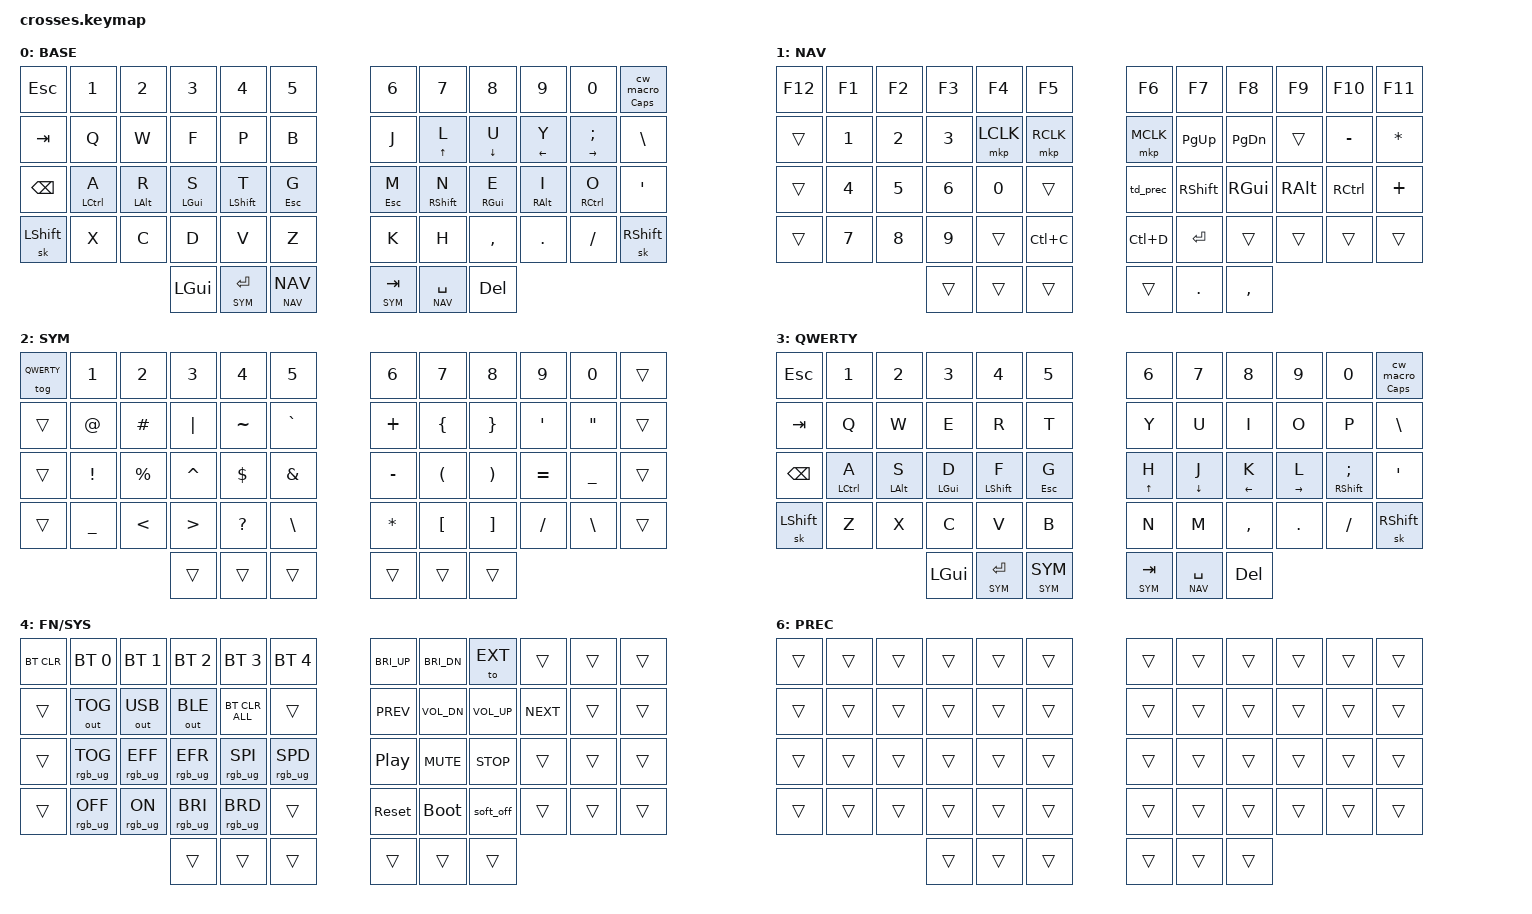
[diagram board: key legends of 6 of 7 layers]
/*
 * Crosses 54 — ZMK keymap (synchronized with eyelash_sofle / kanata.kbd)
 *
 * Layers:
 *   0 = BASE    Colemak-DH + HRMs + top-row hold-arrows
 *   1 = NAV     Navigation / numpad / clipboard shortcuts
 *   2 = SYM     Symbols (+ pos 0 toggles QWERTY)
 *   3 = QWERTY  QWERTY alpha layer (toggle via SYM, pos 0)
 *   4 = FN      Function / media / BT / RGB / system (tri-layer NAV+SYM)
 *   5 = EXT     Extended / special keys (toggle via FN, &to EXT)
 *   6 = PREC    Trackball precision (all &trans; NAV pos 30: hold = on while held,
 *               double-tap = toggle)
 *
 * Home-row & top-row holds (BASE Colemak-DH):
 *   L (mods):   A=Ctrl  R=Alt  S=GUI  T=Shift (hsl)   G=ESC (hla)
 *   R (arrows): L=UP    U=DOWN  Y=LEFT  ;=RIGHT (top row)
 *   R (mods):   M=ESC   N=Shift (hsr)  E=GUI (hmr)  I=Alt (hmr)  O=Ctrl (hmr) (home row)
 *
 * Home-row holds (QWERTY):
 *   L (mods):   A=Ctrl  S=Alt  D=GUI  F=Shift (hsl)   G=ESC (hla)
 *   R (arrows): H=UP    J=DOWN  K=LEFT  L=RIGHT  ;=Shift (hsr)
 */

#include <behaviors.dtsi>
#include <dt-bindings/zmk/bt.h>
#include <dt-bindings/zmk/keys.h>
#include <dt-bindings/zmk/outputs.h>
#include <dt-bindings/zmk/pointing.h>
#include <dt-bindings/zmk/rgb.h>
#include <input/processors.dtsi>

#define BASE   0
#define NAV    1
#define SYM    2
#define QWERTY 3
#define FN     4
#define EXT    5
#define PREC   6

#define LMODS  &kp LCTRL &kp LALT &kp LGUI &kp LSHFT
#define EDIT   &kp K_UNDO &kp K_CUT &kp K_COPY &kp K_PASTE &kp K_REDO

&soft_off { hold-time-ms = <2000>; };

&caps_word { continue-list = <UNDERSCORE MINUS BACKSPACE DELETE>; };

&sk { ignore-modifiers; };

/ {
    chosen { zmk,physical-layout = &gggw_crosses_54_layout; };

    conditional_layers {
        compatible = "zmk,conditional-layers";
        tri_layer {
            if-layers = <NAV SYM>;
            then-layer = <FN>;
        };
    };

    macros {
        cw_macro: cw_macro {
            compatible = "zmk,behavior-macro-one-param";
            #binding-cells = <1>;
            bindings = <&caps_word>;
        };
    };

    behaviors {
        /* Home-row mods (left hand) — Ctrl / Alt / GUI only (A / R / S). */
        hml: home_row_mod_left {
            compatible = "zmk,behavior-hold-tap";
            #binding-cells = <2>;
            flavor = "balanced";
            tapping-term-ms = <280>;
            quick-tap-ms = <175>;
            require-prior-idle-ms = <150>;
            bindings = <&sk>, <&kp>;
            hold-trigger-key-positions = <
                /* Full right hand */
                6  7  8  9  10 11
                18 19 20 21 22 23
                30 31 32 33 34 35
                42 43 44 45 46 47
                51 52 53
            >;
            hold-trigger-on-release;
        };

        /* Left-hand SHIFT (T on Colemak, F on QWERTY) */
        hsl: home_shift_left {
            compatible = "zmk,behavior-hold-tap";
            #binding-cells = <2>;
            flavor = "balanced";
            tapping-term-ms = <280>;
            quick-tap-ms = <175>;
            require-prior-idle-ms = <150>;
            bindings = <&sk>, <&kp>;
            hold-trigger-key-positions = <
                /* Full right hand */
                6  7  8  9  10 11
                18 19 20 21 22 23
                30 31 32 33 34 35
                42 43 44 45 46 47
                51 52 53
            >;
            hold-trigger-on-release;
        };

        /* Right-hand mods (E=GUI, I=Alt, O=Ctrl on Colemak). */
        hmr: home_row_mod_right {
            compatible = "zmk,behavior-hold-tap";
            #binding-cells = <2>;
            flavor = "balanced";
            tapping-term-ms = <280>;
            quick-tap-ms = <175>;
            require-prior-idle-ms = <150>;
            bindings = <&sk>, <&kp>;
            hold-trigger-key-positions = <
                /* Full left hand */
                0  1  2  3  4  5
                12 13 14 15 16 17
                24 25 26 27 28 29
                36 37 38 39 40 41
                48 49 50
            >;
            hold-trigger-on-release;
        };

        /* Right-hand SHIFT (N on Colemak, ; on QWERTY). */
        hsr: home_shift_right {
            compatible = "zmk,behavior-hold-tap";
            #binding-cells = <2>;
            flavor = "balanced";
            tapping-term-ms = <280>;
            quick-tap-ms = <175>;
            require-prior-idle-ms = <150>;
            bindings = <&sk>, <&kp>;
            hold-trigger-key-positions = <
                /* Full left hand */
                0  1  2  3  4  5
                12 13 14 15 16 17
                24 25 26 27 28 29
                36 37 38 39 40 41
                48 49 50
            >;
            hold-trigger-on-release;
        };

        /* Right-hand hold-arrows (top row Colemak, home row QWERTY) & hold-ESC (M) */
        hra: home_row_arrow {
            compatible = "zmk,behavior-hold-tap";
            #binding-cells = <2>;
            flavor = "tap-preferred";
            tapping-term-ms = <200>;
            quick-tap-ms = <175>;
            require-prior-idle-ms = <150>;
            bindings = <&kp>, <&kp>;
            hold-trigger-key-positions = <
                0  1  2  3  4  5
                12 13 14 15 16 17
                24 25 26 27 28 29
                36 37 38 39 40 41
                48 49 50
            >;
            hold-trigger-on-release;
        };

        /* Left-hand hold-arrow (G=ESC) */
        hla: home_left_arrow {
            compatible = "zmk,behavior-hold-tap";
            #binding-cells = <2>;
            flavor = "tap-preferred";
            tapping-term-ms = <200>;
            quick-tap-ms = <175>;
            require-prior-idle-ms = <150>;
            bindings = <&kp>, <&kp>;
            hold-trigger-key-positions = <
                6  7  8  9  10 11
                18 19 20 21 22 23
                30 31 32 33 34 35
                42 43 44 45 46 47
                51 52 53
            >;
            hold-trigger-on-release;
        };

        lt_thumb: layer_tap_thumb {
            compatible = "zmk,behavior-hold-tap";
            #binding-cells = <2>;
            flavor = "tap-preferred";
            tapping-term-ms = <180>;
            quick-tap-ms = <150>;
            bindings = <&mo>, <&kp>;
        };

        ltq: layer_tap_or_sticky {
            compatible = "zmk,behavior-hold-tap";
            #binding-cells = <2>;
            flavor = "balanced";
            tapping-term-ms = <200>;
            quick-tap-ms = <0>;
            bindings = <&mo>, <&sl>;
        };

        kp_slh: kp_tap_sticky_layer_hold {
            compatible = "zmk,behavior-hold-tap";
            #binding-cells = <2>;
            flavor = "tap-preferred";
            tapping-term-ms = <200>;
            quick-tap-ms = <120>;
            require-prior-idle-ms = <150>;
            bindings = <&sl>, <&kp>;
        };

        /* NAV pos 30 (under middle click): hold = precision while held
         * (starts after 200 ms, or at once when another key is pressed),
         * double-tap = toggle precision on/off. */
        td_prec: tap_dance_precision {
            compatible = "zmk,behavior-tap-dance";
            #binding-cells = <0>;
            tapping-term-ms = <200>;
            bindings = <&mo PREC>, <&tog PREC>;
        };

        cw_caps: caps_word_tap_caps_hold {
            compatible = "zmk,behavior-hold-tap";
            #binding-cells = <2>;
            flavor = "tap-preferred";
            tapping-term-ms = <200>;
            quick-tap-ms = <150>;
            bindings = <&kp>, <&cw_macro>;
        };
    };

    keymap {
        compatible = "zmk,keymap";

        /* ==================================================================
         * LAYER 0 — BASE (Colemak-DH)
         * ================================================================== */
        base_layer {
            display-name = "BASE";
            bindings = <
&kp ESC        &kp N1         &kp N2         &kp N3        &kp N4              &kp N5            &kp N6              &kp N7         &kp N8        &kp N9         &kp N0            &cw_caps CAPS 0
&kp TAB        &kp Q          &kp W          &kp F         &kp P               &kp B             &kp J               &hra UP L      &hra DOWN U   &hra LEFT Y    &hra RIGHT SEMI   &kp BSLH
&kp BACKSPACE  &hml LCTRL A   &hml LALT R    &hml LGUI S   &hsl LSHFT T        &hla ESC G        &hra ESC M          &hsr RSHFT N   &hmr RGUI E   &hmr RALT I    &hmr RCTRL O      &kp APOS
&sk LSHFT      &kp X          &kp C          &kp D         &kp V               &kp Z             &kp K               &kp H          &kp COMMA     &kp DOT        &kp FSLH          &sk RSHFT
                                             &kp LGUI      &kp_slh SYM ENTER   &ltq NAV NAV      &lt_thumb SYM TAB   &kp_slh NAV SPACE &kp DEL
            >;
        };

        /* ==================================================================
         * LAYER 1 — NAV
         *   - Left hand: Numpad (1-9), mouse clicks (L/M/R), Cut/Copy
         *   - Right hand: PgUp/PgDn, mods (Shift/GUI/Alt/Ctrl), Return, +, *
         * ================================================================== */
        nav_layer {
            display-name = "NAV";
            bindings = <
&kp F12     &kp F1      &kp F2      &kp F3      &kp F4      &kp F5      &kp F6      &kp F7      &kp F8      &kp F9      &kp F10     &kp F11
&trans      &kp N1      &kp N2      &kp N3      &mkp LCLK   &mkp RCLK   &mkp MCLK   &kp PG_UP   &kp PG_DN   &trans      &kp MINUS   &kp ASTRK
&trans      &kp N4      &kp N5      &kp N6      &kp N0      &trans      &td_prec    &kp RSHFT   &kp RGUI    &kp RALT    &kp RCTRL   &kp PLUS
&trans      &kp N7      &kp N8      &kp N9      &trans      &kp LC(C)   &kp LC(D)   &kp ENTER   &trans      &trans      &trans      &trans
                                    &trans   &trans      &trans      &trans      &kp DOT     &kp COMMA
            >;
        };

        /* ==================================================================
         * LAYER 2 — SYM
         *   Top-left (pos 0) toggles QWERTY (mirrors kanata @tog_qw).
         *   Symbol layout mirrors kanata.kbd / sofle.
         * ================================================================== */
        sym_layer {
            display-name = "SYM";
            bindings = <
&tog QWERTY &kp N1      &kp N2      &kp N3      &kp N4      &kp N5      &kp N6       &kp N7       &kp N8       &kp N9       &kp N0       &trans
&trans      &kp AT      &kp HASH    &kp PIPE    &kp TILDE   &kp GRAVE   &kp PLUS     &kp LBRC     &kp RBRC     &kp APOS     &kp DQT      &trans
&trans      &kp EXCL    &kp PRCNT   &kp CARET   &kp DLLR    &kp AMPS    &kp MINUS    &kp LPAR     &kp RPAR     &kp EQUAL    &kp UNDER    &trans
&trans      &kp UNDER   &kp LT      &kp GT      &kp QMARK   &kp BSLH    &kp ASTRK    &kp LBKT     &kp RBKT     &kp FSLH     &kp BSLH     &trans
                                    &trans      &trans      &trans      &trans       &trans       &trans
            >;
        };

        /* ==================================================================
         * LAYER 3 — QWERTY (toggle via SYM pos 0)
         * ================================================================== */
        qwerty_layer {
            display-name = "QWERTY";
            bindings = <
&kp ESC        &kp N1         &kp N2        &kp N3         &kp N4              &kp N5            &kp N6              &kp N7         &kp N8        &kp N9         &kp N0            &cw_caps CAPS 0
&kp TAB        &kp Q          &kp W         &kp E          &kp R               &kp T             &kp Y               &kp U          &kp I         &kp O          &kp P             &kp BSLH
&kp BACKSPACE  &hml LCTRL A   &hml LALT S   &hml LGUI D    &hsl LSHFT F        &hla ESC G        &hra UP H           &hra DOWN J    &hra LEFT K   &hra RIGHT L   &hsr RSHFT SEMI   &kp APOS
&sk LSHFT      &kp Z          &kp X         &kp C          &kp V               &kp B             &kp N               &kp M          &kp COMMA     &kp DOT        &kp FSLH          &sk RSHFT
                                             &kp LGUI          &kp_slh SYM ENTER &ltq SYM SYM      &lt_thumb SYM TAB   &kp_slh NAV SPACE &kp DEL
            >;
        };

        /* ==================================================================
         * LAYER 4 — FN / Media / System / BT (tri-layer NAV+SYM)
         * ================================================================== */
        fn_layer {
            display-name = "FN/SYS";
            bindings = <
&bt BT_CLR &bt BT_SEL 0     &bt BT_SEL 1      &bt BT_SEL 2     &bt BT_SEL 3     &bt BT_SEL 4      &kp C_BRI_UP  &kp C_BRI_DN  &to EXT      &trans  &trans  &trans
&trans     &out OUT_TOG     &out OUT_USB      &out OUT_BLE     &bt BT_CLR_ALL   &trans            &kp C_PREV    &kp C_VOL_DN  &kp C_VOL_UP &kp C_NEXT &trans &trans
&trans     &rgb_ug RGB_TOG  &rgb_ug RGB_EFF   &rgb_ug RGB_EFR  &rgb_ug RGB_SPI  &rgb_ug RGB_SPD   &kp C_PP      &kp C_MUTE    &kp C_STOP   &trans  &trans  &trans
&trans     &rgb_ug RGB_OFF  &rgb_ug RGB_ON    &rgb_ug RGB_BRI  &rgb_ug RGB_BRD  &trans            &sys_reset    &bootloader   &soft_off    &trans  &trans  &trans
                                              &trans           &trans           &trans            &trans        &trans        &trans
            >;
        };

        /* ==================================================================
         * LAYER 5 — EXT / Special keys (toggle in FN via &to EXT)
         * ================================================================== */
        ext_layer {
            display-name = "EXT";
            bindings = <
&to BASE   &kp PSCRN     &kp SLCK      &kp PAUSE_BREAK  &kp KP_NUM    &trans          &kp INS       &kp HOME      &kp PG_UP     &trans        &trans        &trans
&trans     &kp F11       &kp F12       &kp K_APP        &kp CAPS      &trans          &kp DEL       &kp END       &kp PG_DN     &trans        &trans        &trans
&trans     LMODS                                                      &trans          &kp LEFT      &kp DOWN      &kp UP        &kp RIGHT     &trans        &trans
&trans     EDIT                                                                       &kp K_FIND    &kp C_AL_LOCK &trans        &trans        &trans        &to BASE
                                       &to BASE         &trans        &trans          &to BASE      &trans        &trans
            >;
        };

        /* ==================================================================
         * LAYER 6 — PREC (trackball precision)
         *   All &trans, so keys behave as the layer below. The trackball
         *   listeners in crosses_right.overlay slow the balls on this layer.
         * ================================================================== */
        prec_layer {
            display-name = "PREC";
            bindings = <
&trans &trans &trans &trans &trans &trans  &trans &trans &trans &trans &trans &trans
&trans &trans &trans &trans &trans &trans  &trans &trans &trans &trans &trans &trans
&trans &trans &trans &trans &trans &trans  &trans &trans &trans &trans &trans &trans
&trans &trans &trans &trans &trans &trans  &trans &trans &trans &trans &trans &trans
                     &trans &trans &trans  &trans &trans &trans
            >;
        };
    };
};

/* Right half only. CROSSES_RIGHT_HALF is defined in config/crosses_right.overlay,
 * which only the right half loads. The shield sets the sensor CPI and the
 * listener's base processors after that overlay, so they are overridden here:
 * the keymap loads after the shield. */
#ifdef CROSSES_RIGHT_HALF
&trackball_central {
    /* The PMW3610 only takes 200-CPI steps (850 would round down to 800),
     * so 850 is made from 1000 CPI x 17/20 below. */
    cpi = <1000>;
};

&trackball_central_listener {
    input-processors = <&zip_xy_scaler 18 20>, <&zip_ble_report_rate_limit>;
};
#endif


